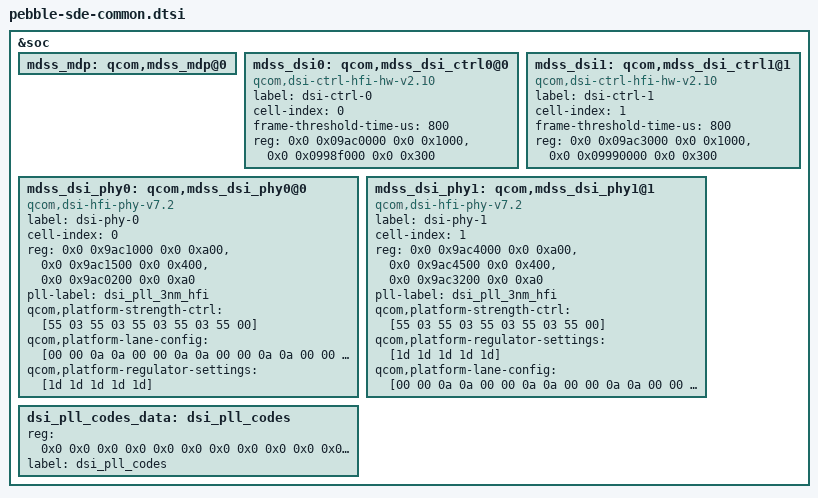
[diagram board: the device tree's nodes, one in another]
// SPDX-License-Identifier: BSD-3-Clause
/*
 * Copyright (c) Qualcomm Technologies, Inc. and/or its subsidiaries.
 */

&soc {
	mdss_mdp: qcom,mdss_mdp@0 {
	};

	mdss_dsi0: qcom,mdss_dsi_ctrl0@0 {
		compatible = "qcom,dsi-ctrl-hfi-hw-v2.10";
		label = "dsi-ctrl-0";
		cell-index = <0>;
		frame-threshold-time-us = <800>;
		reg = <0x0 0x09ac0000 0x0 0x1000>,
			  <0x0 0x0998f000 0x0 0x300>;
		reg-names = "dsi_ctrl", "mdp_intf_base";
	};

	mdss_dsi1: qcom,mdss_dsi_ctrl1@1 {
		compatible = "qcom,dsi-ctrl-hfi-hw-v2.10";
		label = "dsi-ctrl-1";
		cell-index = <1>;
		frame-threshold-time-us = <800>;
		reg = <0x0 0x09ac3000 0x0 0x1000>,
			  <0x0 0x09990000 0x0 0x300>;
		reg-names = "dsi_ctrl", "mdp_intf_base";
	};

	mdss_dsi_phy0: qcom,mdss_dsi_phy0@0 {
		compatible = "qcom,dsi-hfi-phy-v7.2";
		label = "dsi-phy-0";
		cell-index = <0>;
		#clock-cells = <1>;
		reg = <0x0 0x9ac1000 0x0 0xa00>,
		      <0x0 0x9ac1500 0x0 0x400>,
		      <0x0 0x9ac0200 0x0 0xa0>;
		reg-names = "dsi_phy", "pll_base", "dyn_refresh_base";
		pll-label = "dsi_pll_3nm_hfi";

		qcom,platform-strength-ctrl = [55 03
						55 03
						55 03
						55 03
						55 00];
		qcom,platform-lane-config = [00 00 0a 0a
						00 00 0a 0a
						00 00 0a 0a
						00 00 0a 0a
						00 00 8a 8a];
		qcom,platform-regulator-settings = [1d 1d 1d 1d 1d];
	};

	mdss_dsi_phy1: qcom,mdss_dsi_phy1@1 {
		compatible = "qcom,dsi-hfi-phy-v7.2";
		label = "dsi-phy-1";
		cell-index = <1>;
		#clock-cells = <1>;
		reg = <0x0 0x9ac4000 0x0 0xa00>,
		      <0x0 0x9ac4500 0x0 0x400>,
		      <0x0 0x9ac3200 0x0 0xa0>;
		reg-names = "dsi_phy", "pll_base", "dyn_refresh_base";
		pll-label = "dsi_pll_3nm_hfi";

		qcom,platform-strength-ctrl = [55 03
						55 03
						55 03
						55 03
						55 00];
		qcom,platform-regulator-settings = [1d 1d 1d 1d 1d];
		qcom,platform-lane-config = [00 00 0a 0a
						00 00 0a 0a
						00 00 0a 0a
						00 00 0a 0a
						00 00 8a 8a];
	};

	dsi_pll_codes_data:dsi_pll_codes {
		#address-cells = <1>;
		#size-cells = <0>;
		reg = <0x0 0x0 0x0 0x0 0x0 0x0 0x0 0x0 0x0 0x0 0x0 0x0 0x0 0x0 0x0 0x0
			0x0 0x0 0x0 0x0 0x0 0x0 0x0 0x0 0x0 0x0 0x0 0x0 0x0 0x0 0x0 0x0
			0x0 0x0 0x0 0x0 0x0 0x0 0x0 0x0 0x0 0x0 0x0 0x0 0x0 0x0 0x0 0x0
			0x0 0x0 0x0 0x0 0x0 0x0 0x0 0x0 0x0 0x0 0x0 0x0 0x0 0x0 0x0 0x0
			0x0 0x0 0x0 0x0 0x0 0x0 0x0 0x0 0x0 0x0 0x0 0x0 0x0 0x0 0x0 0x0
			0x0 0x0 0x0 0x0 0x0 0x0 0x0 0x0 0x0 0x0 0x0 0x0 0x0 0x0 0x0 0x0
			0x0 0x0 0x0 0x0 0x0 0x0 0x0 0x0 0x0 0x0 0x0 0x0 0x0 0x0 0x0 0x0
			0x0 0x0 0x0 0x0 0x0 0x0 0x0 0x0 0x0 0x0 0x0 0x0 0x0 0x0 0x0 0x0>;
		label = "dsi_pll_codes";
	};
};
